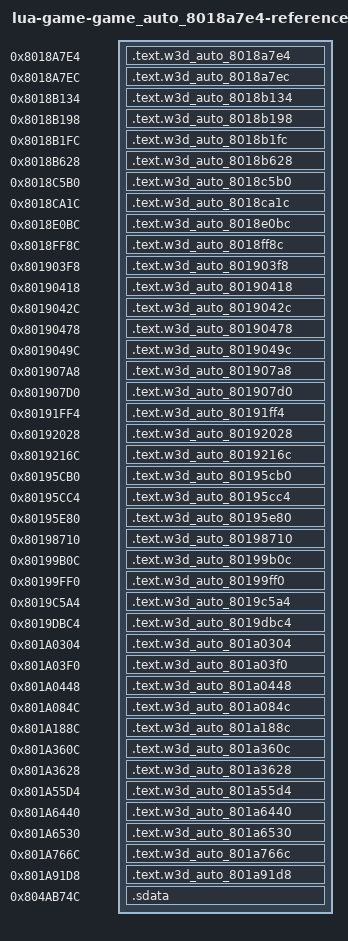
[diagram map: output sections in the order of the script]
/* Generated reference-only placements. All bodies are source-built. */
OUTPUT_FORMAT("elf32-powerpc")
OUTPUT_ARCH(powerpc)
ENTRY(w3d_auto_8018a7e4)
_SDA_BASE_ = 0x804b2540;
_SDA2_BASE_ = 0x804c2540;
fn_8018A864 = 0x8018a864;
fn_8018C60C = 0x8018c60c;
fn_80198FC4 = 0x80198fc4;
fn_801990B8 = 0x801990b8;
fn_801993F8 = 0x801993f8;
fn_8019980C = 0x8019980c;
fn_801998D8 = 0x801998d8;
fn_8019A2A8 = 0x8019a2a8;
fn_801A0338 = 0x801a0338;
fn_801A0384 = 0x801a0384;
fn_801A1008 = 0x801a1008;
fn_801A1A40 = 0x801a1a40;
fn_801A2350 = 0x801a2350;
fn_801B14E8 = 0x801b14e8;
fn_801FE160 = 0x801fe160;
fn_801FE1D8 = 0x801fe1d8;
fn_802098D8 = 0x802098d8;
fn_80209920 = 0x80209920;
fn_80209968 = 0x80209968;
fn_802CD7F4 = 0x802cd7f4;
fn_802CE368 = 0x802ce368;
fn_802D5B00 = 0x802d5b00;
SECTIONS {
  .text.w3d_auto_8018a7e4 0x8018a7e4 : { *(.text.w3d_auto_8018a7e4) }
  .text.w3d_auto_8018a7ec 0x8018a7ec : { *(.text.w3d_auto_8018a7ec) }
  .text.w3d_auto_8018b134 0x8018b134 : { *(.text.w3d_auto_8018b134) }
  .text.w3d_auto_8018b198 0x8018b198 : { *(.text.w3d_auto_8018b198) }
  .text.w3d_auto_8018b1fc 0x8018b1fc : { *(.text.w3d_auto_8018b1fc) }
  .text.w3d_auto_8018b628 0x8018b628 : { *(.text.w3d_auto_8018b628) }
  .text.w3d_auto_8018c5b0 0x8018c5b0 : { *(.text.w3d_auto_8018c5b0) }
  .text.w3d_auto_8018ca1c 0x8018ca1c : { *(.text.w3d_auto_8018ca1c) }
  .text.w3d_auto_8018e0bc 0x8018e0bc : { *(.text.w3d_auto_8018e0bc) }
  .text.w3d_auto_8018ff8c 0x8018ff8c : { *(.text.w3d_auto_8018ff8c) }
  .text.w3d_auto_801903f8 0x801903f8 : { *(.text.w3d_auto_801903f8) }
  .text.w3d_auto_80190418 0x80190418 : { *(.text.w3d_auto_80190418) }
  .text.w3d_auto_8019042c 0x8019042c : { *(.text.w3d_auto_8019042c) }
  .text.w3d_auto_80190478 0x80190478 : { *(.text.w3d_auto_80190478) }
  .text.w3d_auto_8019049c 0x8019049c : { *(.text.w3d_auto_8019049c) }
  .text.w3d_auto_801907a8 0x801907a8 : { *(.text.w3d_auto_801907a8) }
  .text.w3d_auto_801907d0 0x801907d0 : { *(.text.w3d_auto_801907d0) }
  .text.w3d_auto_80191ff4 0x80191ff4 : { *(.text.w3d_auto_80191ff4) }
  .text.w3d_auto_80192028 0x80192028 : { *(.text.w3d_auto_80192028) }
  .text.w3d_auto_8019216c 0x8019216c : { *(.text.w3d_auto_8019216c) }
  .text.w3d_auto_80195cb0 0x80195cb0 : { *(.text.w3d_auto_80195cb0) }
  .text.w3d_auto_80195cc4 0x80195cc4 : { *(.text.w3d_auto_80195cc4) }
  .text.w3d_auto_80195e80 0x80195e80 : { *(.text.w3d_auto_80195e80) }
  .text.w3d_auto_80198710 0x80198710 : { *(.text.w3d_auto_80198710) }
  .text.w3d_auto_80199b0c 0x80199b0c : { *(.text.w3d_auto_80199b0c) }
  .text.w3d_auto_80199ff0 0x80199ff0 : { *(.text.w3d_auto_80199ff0) }
  .text.w3d_auto_8019c5a4 0x8019c5a4 : { *(.text.w3d_auto_8019c5a4) }
  .text.w3d_auto_8019dbc4 0x8019dbc4 : { *(.text.w3d_auto_8019dbc4) }
  .text.w3d_auto_801a0304 0x801a0304 : { *(.text.w3d_auto_801a0304) }
  .text.w3d_auto_801a03f0 0x801a03f0 : { *(.text.w3d_auto_801a03f0) }
  .text.w3d_auto_801a0448 0x801a0448 : { *(.text.w3d_auto_801a0448) }
  .text.w3d_auto_801a084c 0x801a084c : { *(.text.w3d_auto_801a084c) }
  .text.w3d_auto_801a188c 0x801a188c : { *(.text.w3d_auto_801a188c) }
  .text.w3d_auto_801a360c 0x801a360c : { *(.text.w3d_auto_801a360c) }
  .text.w3d_auto_801a3628 0x801a3628 : { *(.text.w3d_auto_801a3628) }
  .text.w3d_auto_801a55d4 0x801a55d4 : { *(.text.w3d_auto_801a55d4) }
  .text.w3d_auto_801a6440 0x801a6440 : { *(.text.w3d_auto_801a6440) }
  .text.w3d_auto_801a6530 0x801a6530 : { *(.text.w3d_auto_801a6530) }
  .text.w3d_auto_801a766c 0x801a766c : { *(.text.w3d_auto_801a766c) }
  .text.w3d_auto_801a91d8 0x801a91d8 : { *(.text.w3d_auto_801a91d8) }
  .sdata 0x804ab74c (NOLOAD) : {
    . = 0x0; lbl_804AB74C = .;
    . = 0x4aec; lbl_804B0238 = .;
    . = 0x4af0; lbl_804B023C = .;
    . = 0x4afc; lbl_804B0248 = .;
    . = 0x4b00; lbl_804B024C = .;
    . = 0x4b08; lbl_804B0254 = .;
    . = 0x4b0c; lbl_804B0258 = .;
    . = 0x4b68; lbl_804B02B4 = .;
    . = 0x6160; lbl_804B18AC = .;
    . = 0x616c; lbl_804B18B8 = .;
    . += 1; }
  /DISCARD/ : { *(.text*) *(.rodata*) *(.data*) *(.bss*) *(.sdata*) *(.sbss*) *(.comment) }
}
